# SMS_LITE_RAT_0_SMS_LITE_TIFS_RAT_MMRS_44200000h register map
Vendor: Texas Instruments
Peripheral module from a debugger description file (folder am62L).
Registers are 32-bit, read-only, reset 0x0 unless marked. A register's access mark holds for its fields unless they carry their own. Offsets are as the file gives them; lines under a group give offsets from that group; [hi:lo] are bit positions; {n}, {i} and the like mark numbered series; 'fields as' and 'values as' point back to an identical list; <NAME> marks a mode.

## SMS_LITE_TIFS_RAT_MMRS
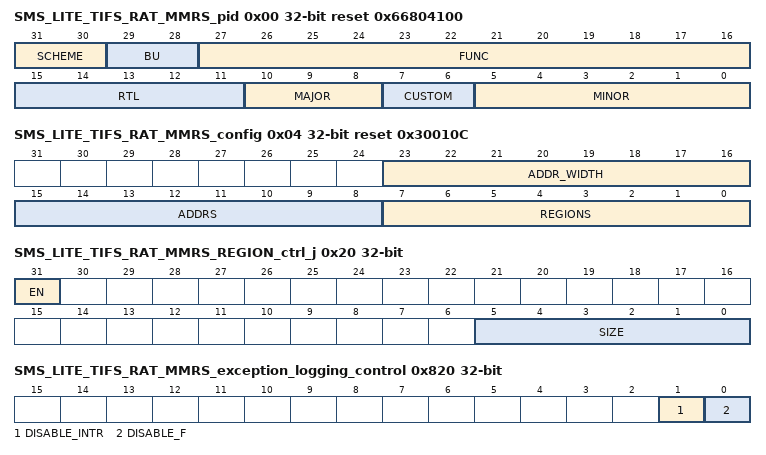
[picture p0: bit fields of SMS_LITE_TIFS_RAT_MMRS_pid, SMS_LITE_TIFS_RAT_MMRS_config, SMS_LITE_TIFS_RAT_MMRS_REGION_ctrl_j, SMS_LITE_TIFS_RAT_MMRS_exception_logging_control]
0x00 SMS_LITE_TIFS_RAT_MMRS_pid reset 0x66804100 — The Revision Register contains the major and minor revisions for the module.
  [31:30] SCHEME — PID register scheme Reset Source: sms_custom_rst_mod_g_rst_n
  [29:28] BU — Business Unit: 10 = Processors Reset Source: sms_custom_rst_mod_g_rst_n
  [27:16] FUNC — Module ID Reset Source: sms_custom_rst_mod_g_rst_n
  [15:11] RTL — RTL revision. Will vary depending on release. Reset Source: sms_custom_rst_mod_g_rst_n
  [10:8] MAJOR — Major revision Reset Source: sms_custom_rst_mod_g_rst_n
  [7:6] CUSTOM — Custom Reset Source: sms_custom_rst_mod_g_rst_n
  [5:0] MINOR — Minor revision Reset Source: sms_custom_rst_mod_g_rst_n
0x04 SMS_LITE_TIFS_RAT_MMRS_config reset 0x30010C — The Config Register contains the configuration values for the module.
  [23:16] ADDR_WIDTH — Number of address bits Reset Source: sms_custom_rst_mod_g_rst_n
  [15:8] ADDRS — Number of addresses Reset Source: sms_custom_rst_mod_g_rst_n
  [7:0] REGIONS — Number of regions Reset Source: sms_custom_rst_mod_g_rst_n
0x20 SMS_LITE_TIFS_RAT_MMRS_REGION_ctrl_j rw — The Control for Region a
  [31] EN — Enable for the Region Reset Source: sms_custom_rst_mod_g_rst_n
  [5:0] SIZE — Size of the Region in Address Bits. 0 = 1 byte, 1 = 2B, 2 = 4B, 3 = 8B, etc. up to 32 = 4GB. Reset Source: sms_custom_rst_mod_g_rst_n
0x24 SMS_LITE_TIFS_RAT_MMRS_REGION_base_j rw — The Base Address for Region a. This is the source address for matching to a region.
  [31:0] BASE — Base Address for the Region. It must be aligned to the programmed size. Reset Source: sms_custom_rst_mod_g_rst_n
0x28 SMS_LITE_TIFS_RAT_MMRS_REGION_trans_l_j rw — The Translated Lower Address Bits for Region a
  [31:0] LOWER — Translated Lower Address Bits for the Region. It must be aligned to the programmed size. Reset Source: sms_custom_rst_mod_g_rst_n
0x2C SMS_LITE_TIFS_RAT_MMRS_REGION_trans_u_j rw — The Translated Upper Address Bits for Region a
  [15:0] UPPER — Translated Upper Address Bits for the Region Reset Source: sms_custom_rst_mod_g_rst_n
0x804 SMS_LITE_TIFS_RAT_MMRS_destination_id rw — The Destination ID Register defines the destination ID value for error messages.
  [7:0] DEST_ID — The destination ID. Reset Source: sms_custom_rst_mod_g_rst_n
0x820 SMS_LITE_TIFS_RAT_MMRS_exception_logging_control rw — The Exception Logging Control Register controls the exception logging.
  [1] DISABLE_INTR — Disables logging interrupt when set. Reset Source: sms_custom_rst_mod_g_rst_n
  [0] DISABLE_F — Disables logging when set. Reset Source: sms_custom_rst_mod_g_rst_n
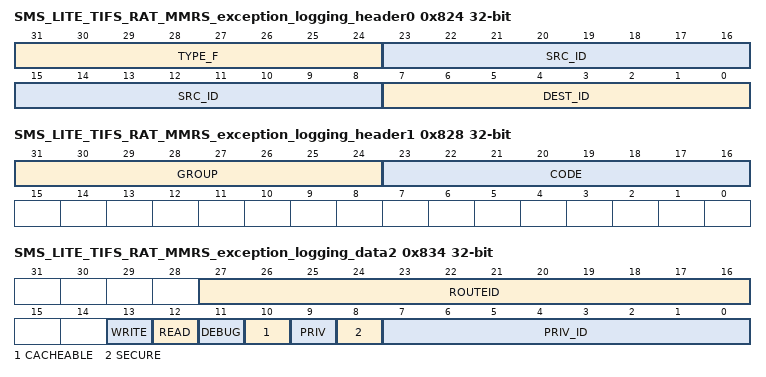
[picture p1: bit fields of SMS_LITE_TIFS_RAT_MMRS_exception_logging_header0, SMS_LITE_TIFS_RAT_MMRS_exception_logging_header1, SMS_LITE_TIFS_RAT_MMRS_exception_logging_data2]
0x824 SMS_LITE_TIFS_RAT_MMRS_exception_logging_header0 — The Exception Logging Header 0 Register contains the first word of the header.
  [31:24] TYPE_F — Type. 4 = RAT. Reset Source: sms_custom_rst_mod_g_rst_n
  [23:8] SRC_ID — Source ID. Reset Source: sms_custom_rst_mod_g_rst_n
  [7:0] DEST_ID — Destination ID. Reset Source: sms_custom_rst_mod_g_rst_n
0x828 SMS_LITE_TIFS_RAT_MMRS_exception_logging_header1 — The Exception Logging Header 1 Register contains the second word of the header.
  [31:24] GROUP — Group. Reset Source: sms_custom_rst_mod_g_rst_n
  [23:16] CODE — Code. 1 = Boundary crossing error. Reset Source: sms_custom_rst_mod_g_rst_n
0x82C SMS_LITE_TIFS_RAT_MMRS_exception_logging_data0 — The Exception Logging Data 0 Register contains the first word of the data.
  [31:0] ADDR_L — Address lower 32 bits. Reset Source: sms_custom_rst_mod_g_rst_n
0x830 SMS_LITE_TIFS_RAT_MMRS_exception_logging_data1 — The Exception Logging Data 1 Register contains the second word of the data.
  [15:0] ADDR_H — Address upper 12 bits. Reset Source: sms_custom_rst_mod_g_rst_n
0x834 SMS_LITE_TIFS_RAT_MMRS_exception_logging_data2 — The Exception Logging Data 2 Register contains the third word of the data.
  [27:16] ROUTEID — Route ID. Reset Source: sms_custom_rst_mod_g_rst_n
  [13] WRITE — Write. Reset Source: sms_custom_rst_mod_g_rst_n
  [12] READ — Read. Reset Source: sms_custom_rst_mod_g_rst_n
  [11] DEBUG — Debug. Reset Source: sms_custom_rst_mod_g_rst_n
  [10] CACHEABLE — Cacheable. Reset Source: sms_custom_rst_mod_g_rst_n
  [9] PRIV — Priv. Reset Source: sms_custom_rst_mod_g_rst_n
  [8] SECURE — Secure. Reset Source: sms_custom_rst_mod_g_rst_n
  [7:0] PRIV_ID — Priv ID. Reset Source: sms_custom_rst_mod_g_rst_n
0x838 SMS_LITE_TIFS_RAT_MMRS_exception_logging_data3 — The Exception Logging Data 3 Register contains the fourth word of the data. Reading this register will clear the error pending bit.
  [9:0] BYTECNT — Byte count. Reset Source: sms_custom_rst_mod_g_rst_n
0x840 SMS_LITE_TIFS_RAT_MMRS_exception_pend_set access not given — The Exception Logging Interrupt Pending Set Register allows to set the pend signal.
  [0] PEND_SET — Write a 1 to set the exception pend signal. Reset Source: sms_custom_rst_mod_g_rst_n (access R/W1TS)
0x844 SMS_LITE_TIFS_RAT_MMRS_exception_pend_clear access not given — The Exception Logging Interrupt Pending Clear Register allows to clear the pend signal.
  [0] PEND_CLR — Write a 1 to clear the exception pend signal. Reset Source: sms_custom_rst_mod_g_rst_n (access R/W1TC)
0x848 SMS_LITE_TIFS_RAT_MMRS_exception_enable_set access not given — The Exception Logging Interrupt Enable Set Register allows to set the interrupt enable signal.
  [0] ENABLE_SET — Write a 1 to set the exception interrupt enable signal. Reset Source: sms_custom_rst_mod_g_rst_n (access R/W1TS)
0x84C SMS_LITE_TIFS_RAT_MMRS_exception_enable_clear access not given — The Exception Logging Interrupt Enable Clear Register allows to clear the interrupt enable signal.
  [0] ENABLE_CLR — Write a 1 to clear the exception interrupt enable signal. Reset Source: sms_custom_rst_mod_g_rst_n (access R/W1TC)
0x850 SMS_LITE_TIFS_RAT_MMRS_eoi_reg rw — EOI Register
  [15:0] EOI_WR — EOI Register Reset Source: sms_custom_rst_mod_g_rst_n
